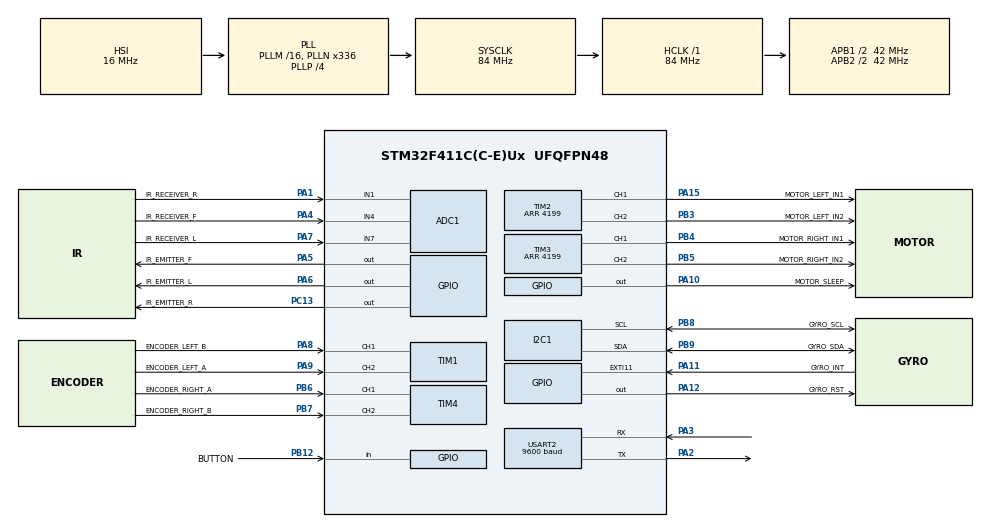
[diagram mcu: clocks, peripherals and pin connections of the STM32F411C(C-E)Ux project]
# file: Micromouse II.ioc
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ADC1.Channel-0\#ChannelRegularConversion=ADC_CHANNEL_4
ADC1.NbrOfConversionFlag=1
ADC1.Rank-0\#ChannelRegularConversion=1
ADC1.SamplingTime-0\#ChannelRegularConversion=ADC_SAMPLETIME_3CYCLES
ADC1.master=1
I2C1.I2C_Mode=I2C_Fast
Mcu.Family=STM32F4
Mcu.Name=STM32F411C(C-E)Ux
Mcu.Package=UFQFPN48
NVIC.EXTI15_10_IRQn=true\:0\:0\:false\:false\:true\:true\:true\:true
NVIC.PriorityGroup=NVIC_PRIORITYGROUP_4
NVIC.USART2_IRQn=true\:0\:0\:false\:false\:true\:true\:true\:true
PA1.GPIO_Label=IR_RECEIVER_R
PA1.Signal=ADCx_IN1
PA10.GPIO_Label=MOTOR_SLEEP
PA10.GPIO_PuPd=GPIO_NOPULL
PA10.Signal=GPIO_Output
PA11.GPIO_Label=GYRO_INT
PA11.Signal=GPXTI11
PA12.GPIO_Label=GYRO_RST
PA12.GPIO_Speed=GPIO_SPEED_FREQ_MEDIUM
PA12.PinState=GPIO_PIN_SET
PA12.Signal=GPIO_Output
PA15.GPIO_Label=MOTOR_LEFT_IN1
PA15.GPIO_Speed=GPIO_SPEED_FREQ_VERY_HIGH
PA15.Signal=S_TIM2_CH1_ETR
PA2.Mode=Asynchronous
PA2.Signal=USART2_TX
PA3.Mode=Asynchronous
PA3.Signal=USART2_RX
PA4.GPIO_Label=IR_RECEIVER_F
PA4.Signal=ADCx_IN4
PA5.GPIO_Label=IR_EMITTER_F
PA5.GPIO_Speed=GPIO_SPEED_FREQ_MEDIUM
PA5.Signal=GPIO_Output
PA6.GPIO_Label=IR_EMITTER_L
PA6.GPIO_Speed=GPIO_SPEED_FREQ_MEDIUM
PA6.Signal=GPIO_Output
PA7.GPIO_Label=IR_RECEIVER_L
PA7.Signal=ADCx_IN7
PA8.GPIO_Label=ENCODER_LEFT_B
PA8.Signal=S_TIM1_CH1
PA9.GPIO_Label=ENCODER_LEFT_A
PA9.Signal=S_TIM1_CH2
PB12.GPIO_Label=BUTTON
PB12.GPIO_PuPd=GPIO_PULLUP
PB12.Signal=GPIO_Input
PB3.GPIO_Label=MOTOR_LEFT_IN2
PB3.GPIO_Speed=GPIO_SPEED_FREQ_VERY_HIGH
PB3.Signal=S_TIM2_CH2
PB4.GPIO_Label=MOTOR_RIGHT_IN1
PB4.GPIO_Speed=GPIO_SPEED_FREQ_VERY_HIGH
PB4.Signal=S_TIM3_CH1
PB5.GPIO_Label=MOTOR_RIGHT_IN2
PB5.GPIO_Speed=GPIO_SPEED_FREQ_VERY_HIGH
PB5.Signal=S_TIM3_CH2
PB6.GPIO_Label=ENCODER_RIGHT_A
PB6.Signal=S_TIM4_CH1
PB7.GPIO_Label=ENCODER_RIGHT_B
PB7.Signal=S_TIM4_CH2
PB8.GPIO_Label=GYRO_SCL
PB8.Mode=I2C
PB8.Signal=I2C1_SCL
PB9.GPIO_Label=GYRO_SDA
PB9.Mode=I2C
PB9.Signal=I2C1_SDA
PC13-ANTI_TAMP.GPIO_Label=IR_EMITTER_R
PC13-ANTI_TAMP.Signal=GPIO_Output
ProjectManager.HeapSize=0x200
ProjectManager.StackSize=0x400
ProjectManager.TargetToolchain=STM32CubeIDE
RCC.48MHZClocksFreq_Value=84000000
RCC.AHBFreq_Value=84000000
RCC.APB1CLKDivider=RCC_HCLK_DIV2
RCC.APB1Freq_Value=42000000
RCC.APB1TimFreq_Value=84000000
RCC.APB2CLKDivider=RCC_HCLK_DIV2
RCC.APB2Freq_Value=42000000
RCC.APB2TimFreq_Value=84000000
RCC.CortexFreq_Value=84000000
RCC.HCLKFreq_Value=84000000
RCC.HSE_VALUE=25000000
RCC.HSI_VALUE=16000000
RCC.LSE_VALUE=32768
RCC.PLLN=336
RCC.PLLP=RCC_PLLP_DIV4
RCC.SYSCLKFreq_VALUE=84000000
RCC.SYSCLKSource=RCC_SYSCLKSOURCE_PLLCLK
RCC.VCOOutputFreq_Value=336000000
SH.ADCx_IN1.0=ADC1_IN1,IN1
SH.ADCx_IN4.0=ADC1_IN4,IN4
SH.ADCx_IN7.0=ADC1_IN7,IN7
SH.S_TIM1_CH1.0=TIM1_CH1,Encoder_Interface
SH.S_TIM1_CH2.0=TIM1_CH2,Encoder_Interface
SH.S_TIM2_CH1_ETR.0=TIM2_CH1,PWM Generation1 CH1
SH.S_TIM2_CH2.0=TIM2_CH2,PWM Generation2 CH2
SH.S_TIM3_CH1.0=TIM3_CH1,PWM Generation1 CH1
SH.S_TIM3_CH2.0=TIM3_CH2,PWM Generation2 CH2
SH.S_TIM4_CH1.0=TIM4_CH1,Encoder_Interface
SH.S_TIM4_CH2.0=TIM4_CH2,Encoder_Interface
TIM2.AutoReloadPreload=TIM_AUTORELOAD_PRELOAD_ENABLE
TIM2.Channel-PWM\ Generation1\ CH1=TIM_CHANNEL_1
TIM2.Channel-PWM\ Generation2\ CH2=TIM_CHANNEL_2
TIM2.Period=4199
TIM3.AutoReloadPreload=TIM_AUTORELOAD_PRELOAD_ENABLE
TIM3.Channel-PWM\ Generation1\ CH1=TIM_CHANNEL_1
TIM3.Channel-PWM\ Generation2\ CH2=TIM_CHANNEL_2
TIM3.Period=4199
USART2.BaudRate=9600
USART2.VirtualMode=VM_ASYNC
VP_TIM2_VS_ClockSourceINT.Mode=Internal
VP_TIM3_VS_ClockSourceINT.Mode=Internal
board=custom

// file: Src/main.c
/* USER CODE BEGIN Header */
/**
  ******************************************************************************
  * @file           : main.c
  * @brief          : Main program body
  ******************************************************************************
  * @attention
  *
  * Copyright (c) 2026 STMicroelectronics.
  * All rights reserved.
  *
  * This software is licensed under terms that can be found in the LICENSE file
  * in the root directory of this software component.
  * If no LICENSE file comes with this software, it is provided AS-IS.
  *
  ******************************************************************************
  */
/* USER CODE END Header */
#include "main.h"

/* USER CODE BEGIN Includes */
#include "calibration.h"
/* USER CODE END Includes */

/* USER CODE BEGIN PD */
#define MODE_CALIBRATION  0
#define MODE_RUN          1
#define CURRENT_MODE      MODE_CALIBRATION
/* USER CODE END PD */

ADC_HandleTypeDef hadc1;

I2C_HandleTypeDef hi2c1;

TIM_HandleTypeDef htim1;
TIM_HandleTypeDef htim2;
TIM_HandleTypeDef htim3;
TIM_HandleTypeDef htim4;

UART_HandleTypeDef huart2;

void SystemClock_Config(void);
static void MX_GPIO_Init(void);
static void MX_TIM1_Init(void);
static void MX_TIM4_Init(void);
static void MX_TIM2_Init(void);
static void MX_TIM3_Init(void);
static void MX_I2C1_Init(void);
static void MX_USART2_UART_Init(void);
static void MX_ADC1_Init(void);

int main(void)
{

  /* MCU Configuration--------------------------------------------------------*/

  /* Reset of all peripherals, Initializes the Flash interface and the Systick. */
  HAL_Init();

  /* Configure the system clock */
  SystemClock_Config();

  /* Initialize all configured peripherals */
  MX_GPIO_Init();
  MX_TIM1_Init();
  MX_TIM4_Init();
  MX_TIM2_Init();
  MX_TIM3_Init();
  MX_I2C1_Init();
  MX_USART2_UART_Init();
  MX_ADC1_Init();
  /* USER CODE BEGIN 2 */
  #if CURRENT_MODE == MODE_CALIBRATION
     Calibration_Run();
  #endif
  /* USER CODE END 2 */

  /* Infinite loop */
  while (1)
  {

  }
}

void SystemClock_Config(void)
{
  RCC_OscInitTypeDef RCC_OscInitStruct = {0};
  RCC_ClkInitTypeDef RCC_ClkInitStruct = {0};

  /** Configure the main internal regulator output voltage
  */
  __HAL_RCC_PWR_CLK_ENABLE();
  __HAL_PWR_VOLTAGESCALING_CONFIG(PWR_REGULATOR_VOLTAGE_SCALE1);

  /** Initializes the RCC Oscillators according to the specified parameters
  * in the RCC_OscInitTypeDef structure.
  */
  RCC_OscInitStruct.OscillatorType = RCC_OSCILLATORTYPE_HSI;
  RCC_OscInitStruct.HSIState = RCC_HSI_ON;
  RCC_OscInitStruct.HSICalibrationValue = RCC_HSICALIBRATION_DEFAULT;
  RCC_OscInitStruct.PLL.PLLState = RCC_PLL_ON;
  RCC_OscInitStruct.PLL.PLLSource = RCC_PLLSOURCE_HSI;
  RCC_OscInitStruct.PLL.PLLM = 16;
  RCC_OscInitStruct.PLL.PLLN = 336;
  RCC_OscInitStruct.PLL.PLLP = RCC_PLLP_DIV4;
  RCC_OscInitStruct.PLL.PLLQ = 4;
  if (HAL_RCC_OscConfig(&RCC_OscInitStruct) != HAL_OK)
  {
    Error_Handler();
  }

  /** Initializes the CPU, AHB and APB buses clocks
  */
  RCC_ClkInitStruct.ClockType = RCC_CLOCKTYPE_HCLK|RCC_CLOCKTYPE_SYSCLK
                              |RCC_CLOCKTYPE_PCLK1|RCC_CLOCKTYPE_PCLK2;
  RCC_ClkInitStruct.SYSCLKSource = RCC_SYSCLKSOURCE_PLLCLK;
  RCC_ClkInitStruct.AHBCLKDivider = RCC_SYSCLK_DIV1;
  RCC_ClkInitStruct.APB1CLKDivider = RCC_HCLK_DIV2;
  RCC_ClkInitStruct.APB2CLKDivider = RCC_HCLK_DIV2;

  if (HAL_RCC_ClockConfig(&RCC_ClkInitStruct, FLASH_LATENCY_2) != HAL_OK)
  {
    Error_Handler();
  }
}

static void MX_ADC1_Init(void)
{

  ADC_ChannelConfTypeDef sConfig = {0};

  /** Configure the global features of the ADC (Clock, Resolution, Data Alignment and number of conversion)
  */
  hadc1.Instance = ADC1;
  hadc1.Init.ClockPrescaler = ADC_CLOCK_SYNC_PCLK_DIV2;
  hadc1.Init.Resolution = ADC_RESOLUTION_12B;
  hadc1.Init.ScanConvMode = DISABLE;
  hadc1.Init.ContinuousConvMode = DISABLE;
  hadc1.Init.DiscontinuousConvMode = DISABLE;
  hadc1.Init.ExternalTrigConvEdge = ADC_EXTERNALTRIGCONVEDGE_NONE;
  hadc1.Init.ExternalTrigConv = ADC_SOFTWARE_START;
  hadc1.Init.DataAlign = ADC_DATAALIGN_RIGHT;
  hadc1.Init.NbrOfConversion = 1;
  hadc1.Init.DMAContinuousRequests = DISABLE;
  hadc1.Init.EOCSelection = ADC_EOC_SINGLE_CONV;
  if (HAL_ADC_Init(&hadc1) != HAL_OK)
  {
    Error_Handler();
  }

  /** Configure for the selected ADC regular channel its corresponding rank in the sequencer and its sample time.
  */
  sConfig.Channel = ADC_CHANNEL_4;
  sConfig.Rank = 1;
  sConfig.SamplingTime = ADC_SAMPLETIME_3CYCLES;
  if (HAL_ADC_ConfigChannel(&hadc1, &sConfig) != HAL_OK)
  {
    Error_Handler();
  }

}

static void MX_I2C1_Init(void)
{

  hi2c1.Instance = I2C1;
  hi2c1.Init.ClockSpeed = 400000;
  hi2c1.Init.DutyCycle = I2C_DUTYCYCLE_2;
  hi2c1.Init.OwnAddress1 = 0;
  hi2c1.Init.AddressingMode = I2C_ADDRESSINGMODE_7BIT;
  hi2c1.Init.DualAddressMode = I2C_DUALADDRESS_DISABLE;
  hi2c1.Init.OwnAddress2 = 0;
  hi2c1.Init.GeneralCallMode = I2C_GENERALCALL_DISABLE;
  hi2c1.Init.NoStretchMode = I2C_NOSTRETCH_DISABLE;
  if (HAL_I2C_Init(&hi2c1) != HAL_OK)
  {
    Error_Handler();
  }

}

static void MX_TIM1_Init(void)
{

  TIM_Encoder_InitTypeDef sConfig = {0};
  TIM_MasterConfigTypeDef sMasterConfig = {0};

  htim1.Instance = TIM1;
  htim1.Init.Prescaler = 0;
  htim1.Init.CounterMode = TIM_COUNTERMODE_UP;
  htim1.Init.Period = 65535;
  htim1.Init.ClockDivision = TIM_CLOCKDIVISION_DIV1;
  htim1.Init.RepetitionCounter = 0;
  htim1.Init.AutoReloadPreload = TIM_AUTORELOAD_PRELOAD_DISABLE;
  sConfig.EncoderMode = TIM_ENCODERMODE_TI1;
  sConfig.IC1Polarity = TIM_ICPOLARITY_RISING;
  sConfig.IC1Selection = TIM_ICSELECTION_DIRECTTI;
  sConfig.IC1Prescaler = TIM_ICPSC_DIV1;
  sConfig.IC1Filter = 0;
  sConfig.IC2Polarity = TIM_ICPOLARITY_RISING;
  sConfig.IC2Selection = TIM_ICSELECTION_DIRECTTI;
  sConfig.IC2Prescaler = TIM_ICPSC_DIV1;
  sConfig.IC2Filter = 0;
  if (HAL_TIM_Encoder_Init(&htim1, &sConfig) != HAL_OK)
  {
    Error_Handler();
  }
  sMasterConfig.MasterOutputTrigger = TIM_TRGO_RESET;
  sMasterConfig.MasterSlaveMode = TIM_MASTERSLAVEMODE_DISABLE;
  if (HAL_TIMEx_MasterConfigSynchronization(&htim1, &sMasterConfig) != HAL_OK)
  {
    Error_Handler();
  }

}

static void MX_TIM2_Init(void)
{

  TIM_ClockConfigTypeDef sClockSourceConfig = {0};
  TIM_MasterConfigTypeDef sMasterConfig = {0};
  TIM_OC_InitTypeDef sConfigOC = {0};

  htim2.Instance = TIM2;
  htim2.Init.Prescaler = 0;
  htim2.Init.CounterMode = TIM_COUNTERMODE_UP;
  htim2.Init.Period = 4199;
  htim2.Init.ClockDivision = TIM_CLOCKDIVISION_DIV1;
  htim2.Init.AutoReloadPreload = TIM_AUTORELOAD_PRELOAD_ENABLE;
  if (HAL_TIM_Base_Init(&htim2) != HAL_OK)
  {
    Error_Handler();
  }
  sClockSourceConfig.ClockSource = TIM_CLOCKSOURCE_INTERNAL;
  if (HAL_TIM_ConfigClockSource(&htim2, &sClockSourceConfig) != HAL_OK)
  {
    Error_Handler();
  }
  if (HAL_TIM_PWM_Init(&htim2) != HAL_OK)
  {
    Error_Handler();
  }
  sMasterConfig.MasterOutputTrigger = TIM_TRGO_RESET;
  sMasterConfig.MasterSlaveMode = TIM_MASTERSLAVEMODE_DISABLE;
  if (HAL_TIMEx_MasterConfigSynchronization(&htim2, &sMasterConfig) != HAL_OK)
  {
    Error_Handler();
  }
  sConfigOC.OCMode = TIM_OCMODE_PWM1;
  sConfigOC.Pulse = 0;
  sConfigOC.OCPolarity = TIM_OCPOLARITY_HIGH;
  sConfigOC.OCFastMode = TIM_OCFAST_DISABLE;
  if (HAL_TIM_PWM_ConfigChannel(&htim2, &sConfigOC, TIM_CHANNEL_1) != HAL_OK)
  {
    Error_Handler();
  }
  if (HAL_TIM_PWM_ConfigChannel(&htim2, &sConfigOC, TIM_CHANNEL_2) != HAL_OK)
  {
    Error_Handler();
  }
  HAL_TIM_MspPostInit(&htim2);

}

static void MX_TIM3_Init(void)
{

  TIM_ClockConfigTypeDef sClockSourceConfig = {0};
  TIM_MasterConfigTypeDef sMasterConfig = {0};
  TIM_OC_InitTypeDef sConfigOC = {0};

  htim3.Instance = TIM3;
  htim3.Init.Prescaler = 0;
  htim3.Init.CounterMode = TIM_COUNTERMODE_UP;
  htim3.Init.Period = 4199;
  htim3.Init.ClockDivision = TIM_CLOCKDIVISION_DIV1;
  htim3.Init.AutoReloadPreload = TIM_AUTORELOAD_PRELOAD_ENABLE;
  if (HAL_TIM_Base_Init(&htim3) != HAL_OK)
  {
    Error_Handler();
  }
  sClockSourceConfig.ClockSource = TIM_CLOCKSOURCE_INTERNAL;
  if (HAL_TIM_ConfigClockSource(&htim3, &sClockSourceConfig) != HAL_OK)
  {
    Error_Handler();
  }
  if (HAL_TIM_PWM_Init(&htim3) != HAL_OK)
  {
    Error_Handler();
  }
  sMasterConfig.MasterOutputTrigger = TIM_TRGO_RESET;
  sMasterConfig.MasterSlaveMode = TIM_MASTERSLAVEMODE_DISABLE;
  if (HAL_TIMEx_MasterConfigSynchronization(&htim3, &sMasterConfig) != HAL_OK)
  {
    Error_Handler();
  }
  sConfigOC.OCMode = TIM_OCMODE_PWM1;
  sConfigOC.Pulse = 0;
  sConfigOC.OCPolarity = TIM_OCPOLARITY_HIGH;
  sConfigOC.OCFastMode = TIM_OCFAST_DISABLE;
  if (HAL_TIM_PWM_ConfigChannel(&htim3, &sConfigOC, TIM_CHANNEL_1) != HAL_OK)
  {
    Error_Handler();
  }
  if (HAL_TIM_PWM_ConfigChannel(&htim3, &sConfigOC, TIM_CHANNEL_2) != HAL_OK)
  {
    Error_Handler();
  }
  HAL_TIM_MspPostInit(&htim3);

}

static void MX_TIM4_Init(void)
{

  TIM_Encoder_InitTypeDef sConfig = {0};
  TIM_MasterConfigTypeDef sMasterConfig = {0};

  htim4.Instance = TIM4;
  htim4.Init.Prescaler = 0;
  htim4.Init.CounterMode = TIM_COUNTERMODE_UP;
  htim4.Init.Period = 65535;
  htim4.Init.ClockDivision = TIM_CLOCKDIVISION_DIV1;
  htim4.Init.AutoReloadPreload = TIM_AUTORELOAD_PRELOAD_DISABLE;
  sConfig.EncoderMode = TIM_ENCODERMODE_TI1;
  sConfig.IC1Polarity = TIM_ICPOLARITY_RISING;
  sConfig.IC1Selection = TIM_ICSELECTION_DIRECTTI;
  sConfig.IC1Prescaler = TIM_ICPSC_DIV1;
  sConfig.IC1Filter = 0;
  sConfig.IC2Polarity = TIM_ICPOLARITY_RISING;
  sConfig.IC2Selection = TIM_ICSELECTION_DIRECTTI;
  sConfig.IC2Prescaler = TIM_ICPSC_DIV1;
  sConfig.IC2Filter = 0;
  if (HAL_TIM_Encoder_Init(&htim4, &sConfig) != HAL_OK)
  {
    Error_Handler();
  }
  sMasterConfig.MasterOutputTrigger = TIM_TRGO_RESET;
  sMasterConfig.MasterSlaveMode = TIM_MASTERSLAVEMODE_DISABLE;
  if (HAL_TIMEx_MasterConfigSynchronization(&htim4, &sMasterConfig) != HAL_OK)
  {
    Error_Handler();
  }

}

static void MX_USART2_UART_Init(void)
{

  huart2.Instance = USART2;
  huart2.Init.BaudRate = 9600;
  huart2.Init.WordLength = UART_WORDLENGTH_8B;
  huart2.Init.StopBits = UART_STOPBITS_1;
  huart2.Init.Parity = UART_PARITY_NONE;
  huart2.Init.Mode = UART_MODE_TX_RX;
  huart2.Init.HwFlowCtl = UART_HWCONTROL_NONE;
  huart2.Init.OverSampling = UART_OVERSAMPLING_16;
  if (HAL_UART_Init(&huart2) != HAL_OK)
  {
    Error_Handler();
  }

}

static void MX_GPIO_Init(void)
{
  GPIO_InitTypeDef GPIO_InitStruct = {0};

  /* GPIO Ports Clock Enable */
  __HAL_RCC_GPIOC_CLK_ENABLE();
  __HAL_RCC_GPIOA_CLK_ENABLE();
  __HAL_RCC_GPIOB_CLK_ENABLE();

  /*Configure GPIO pin Output Level */
  HAL_GPIO_WritePin(IR_EMITTER_R_GPIO_Port, IR_EMITTER_R_Pin, GPIO_PIN_RESET);

  /*Configure GPIO pin Output Level */
  HAL_GPIO_WritePin(GPIOA, IR_EMITTER_F_Pin|IR_EMITTER_L_Pin|MOTOR_SLEEP_Pin, GPIO_PIN_RESET);

  /*Configure GPIO pin Output Level */
  HAL_GPIO_WritePin(GYRO_RST_GPIO_Port, GYRO_RST_Pin, GPIO_PIN_SET);

  /*Configure GPIO pin : IR_EMITTER_R_Pin */
  GPIO_InitStruct.Pin = IR_EMITTER_R_Pin;
  GPIO_InitStruct.Mode = GPIO_MODE_OUTPUT_PP;
  GPIO_InitStruct.Pull = GPIO_NOPULL;
  GPIO_InitStruct.Speed = GPIO_SPEED_FREQ_LOW;
  HAL_GPIO_Init(IR_EMITTER_R_GPIO_Port, &GPIO_InitStruct);

  /*Configure GPIO pins : IR_EMITTER_F_Pin IR_EMITTER_L_Pin GYRO_RST_Pin */
  GPIO_InitStruct.Pin = IR_EMITTER_F_Pin|IR_EMITTER_L_Pin|GYRO_RST_Pin;
  GPIO_InitStruct.Mode = GPIO_MODE_OUTPUT_PP;
  GPIO_InitStruct.Pull = GPIO_NOPULL;
  GPIO_InitStruct.Speed = GPIO_SPEED_FREQ_MEDIUM;
  HAL_GPIO_Init(GPIOA, &GPIO_InitStruct);

  /*Configure GPIO pin : BUTTON_Pin */
  GPIO_InitStruct.Pin = BUTTON_Pin;
  GPIO_InitStruct.Mode = GPIO_MODE_INPUT;
  GPIO_InitStruct.Pull = GPIO_PULLUP;
  HAL_GPIO_Init(BUTTON_GPIO_Port, &GPIO_InitStruct);

  /*Configure GPIO pin : MOTOR_SLEEP_Pin */
  GPIO_InitStruct.Pin = MOTOR_SLEEP_Pin;
  GPIO_InitStruct.Mode = GPIO_MODE_OUTPUT_PP;
  GPIO_InitStruct.Pull = GPIO_NOPULL;
  GPIO_InitStruct.Speed = GPIO_SPEED_FREQ_LOW;
  HAL_GPIO_Init(MOTOR_SLEEP_GPIO_Port, &GPIO_InitStruct);

  /*Configure GPIO pin : GYRO_INT_Pin */
  GPIO_InitStruct.Pin = GYRO_INT_Pin;
  GPIO_InitStruct.Mode = GPIO_MODE_IT_RISING;
  GPIO_InitStruct.Pull = GPIO_NOPULL;
  HAL_GPIO_Init(GYRO_INT_GPIO_Port, &GPIO_InitStruct);

  /* EXTI interrupt init*/
  HAL_NVIC_SetPriority(EXTI15_10_IRQn, 0, 0);
  HAL_NVIC_EnableIRQ(EXTI15_10_IRQn);

}

void Error_Handler(void)
{
  __disable_irq();
  while (1)
  {
  }
}
